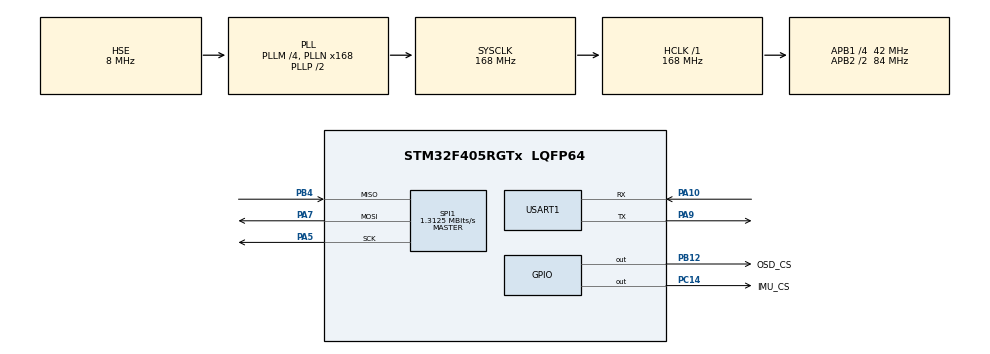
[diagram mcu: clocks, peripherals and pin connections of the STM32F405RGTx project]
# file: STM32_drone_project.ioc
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Mcu.Family=STM32F4
Mcu.Name=STM32F405RGTx
Mcu.Package=LQFP64
NVIC.PriorityGroup=NVIC_PRIORITYGROUP_4
PA10.Mode=Asynchronous
PA10.Signal=USART1_RX
PA13.Mode=Serial_Wire
PA13.Signal=SYS_JTMS-SWDIO
PA14.Mode=Serial_Wire
PA14.Signal=SYS_JTCK-SWCLK
PA5.Mode=Full_Duplex_Master
PA5.Signal=SPI1_SCK
PA7.Mode=Full_Duplex_Master
PA7.Signal=SPI1_MOSI
PA9.Mode=Asynchronous
PA9.Signal=USART1_TX
PB12.GPIO_Label=OSD_CS
PB12.GPIO_Speed=GPIO_SPEED_FREQ_LOW
PB12.PinState=GPIO_PIN_SET
PB12.Signal=GPIO_Output
PB4.Mode=Full_Duplex_Master
PB4.Signal=SPI1_MISO
PC14-OSC32_IN.GPIO_Label=IMU_CS
PC14-OSC32_IN.PinState=GPIO_PIN_SET
PC14-OSC32_IN.Signal=GPIO_Output
PH0-OSC_IN.Mode=HSE-External-Oscillator
PH0-OSC_IN.Signal=RCC_OSC_IN
PH1-OSC_OUT.Mode=HSE-External-Oscillator
PH1-OSC_OUT.Signal=RCC_OSC_OUT
ProjectManager.HeapSize=0x200
ProjectManager.StackSize=0x400
ProjectManager.TargetToolchain=STM32CubeIDE
RCC.48MHZClocksFreq_Value=84000000
RCC.AHBFreq_Value=168000000
RCC.APB1CLKDivider=RCC_HCLK_DIV4
RCC.APB1Freq_Value=42000000
RCC.APB1TimFreq_Value=84000000
RCC.APB2CLKDivider=RCC_HCLK_DIV2
RCC.APB2Freq_Value=84000000
RCC.APB2TimFreq_Value=168000000
RCC.CortexFreq_Value=168000000
RCC.HCLKFreq_Value=168000000
RCC.HSE_VALUE=8000000
RCC.HSI_VALUE=16000000
RCC.LSE_VALUE=32768
RCC.PLLM=4
RCC.PLLN=168
RCC.PLLSourceVirtual=RCC_PLLSOURCE_HSE
RCC.SYSCLKFreq_VALUE=168000000
RCC.SYSCLKSource=RCC_SYSCLKSOURCE_PLLCLK
RCC.VCOOutputFreq_Value=336000000
SPI1.BaudRatePrescaler=SPI_BAUDRATEPRESCALER_64
SPI1.CLKPhase=SPI_PHASE_2EDGE
SPI1.CLKPolarity=SPI_POLARITY_HIGH
SPI1.CalculateBaudRate=1.3125 MBits/s
SPI1.Direction=SPI_DIRECTION_2LINES
SPI1.Mode=SPI_MODE_MASTER
SPI1.VirtualType=VM_MASTER
USART1.VirtualMode=VM_ASYNC
board=custom

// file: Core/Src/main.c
/* USER CODE BEGIN Header */
/**
  ******************************************************************************
  * @file           : main.c
  * @brief          : Main program body
  ******************************************************************************
  * @attention
  *
  * Copyright (c) 2026 STMicroelectronics.
  * All rights reserved.
  *
  * This software is licensed under terms that can be found in the LICENSE file
  * in the root directory of this software component.
  * If no LICENSE file comes with this software, it is provided AS-IS.
  *
  ******************************************************************************
  */
/* USER CODE END Header */
#include "main.h"

SPI_HandleTypeDef hspi1;

UART_HandleTypeDef huart1;

/* USER CODE BEGIN PV */
volatile uint8_t g_who_am_i = 0;
volatile uint8_t g_rx0 = 0, g_rx1 = 0;
volatile int g_spi_status = -1;
/* USER CODE END PV */

void SystemClock_Config(void);
static void MX_GPIO_Init(void);
static void MX_USART1_UART_Init(void);
static void MX_SPI1_Init(void);

int main(void)
{

  /* MCU Configuration--------------------------------------------------------*/

  /* Reset of all peripherals, Initializes the Flash interface and the Systick. */
  HAL_Init();

  /* Configure the system clock */
  SystemClock_Config();

  /* Initialize all configured peripherals */
  MX_GPIO_Init();
  MX_USART1_UART_Init();
  MX_SPI1_Init();
  /* USER CODE BEGIN 2 */
	HAL_Delay(50);

	__HAL_SPI_ENABLE(&hspi1); /* ① 클록 선을 먼저 '쉬는 위치(High)'로 */
	HAL_Delay(1);

	uint8_t tx[2] = { 0x75 | 0x80, 0x00 };
	uint8_t rx[2] = { 0xAA, 0xAA }; /* ② 일부러 0이 아닌 값으로 시작 */

	HAL_GPIO_WritePin(IMU_CS_GPIO_Port, IMU_CS_Pin, GPIO_PIN_RESET);
	g_spi_status = HAL_SPI_TransmitReceive(&hspi1, tx, rx, 2, 100); /* ③ 성공 여부 저장 */
	HAL_GPIO_WritePin(IMU_CS_GPIO_Port, IMU_CS_Pin, GPIO_PIN_SET);

	g_rx0 = rx[0];
	g_rx1 = rx[1];
	g_who_am_i = rx[1];
  /* USER CODE END 2 */

  /* Infinite loop */
  while (1)
  {

  }
}

void SystemClock_Config(void)
{
  RCC_OscInitTypeDef RCC_OscInitStruct = {0};
  RCC_ClkInitTypeDef RCC_ClkInitStruct = {0};

  /** Configure the main internal regulator output voltage
  */
  __HAL_RCC_PWR_CLK_ENABLE();
  __HAL_PWR_VOLTAGESCALING_CONFIG(PWR_REGULATOR_VOLTAGE_SCALE1);

  /** Initializes the RCC Oscillators according to the specified parameters
  * in the RCC_OscInitTypeDef structure.
  */
  RCC_OscInitStruct.OscillatorType = RCC_OSCILLATORTYPE_HSE;
  RCC_OscInitStruct.HSEState = RCC_HSE_ON;
  RCC_OscInitStruct.PLL.PLLState = RCC_PLL_ON;
  RCC_OscInitStruct.PLL.PLLSource = RCC_PLLSOURCE_HSE;
  RCC_OscInitStruct.PLL.PLLM = 4;
  RCC_OscInitStruct.PLL.PLLN = 168;
  RCC_OscInitStruct.PLL.PLLP = RCC_PLLP_DIV2;
  RCC_OscInitStruct.PLL.PLLQ = 4;
  if (HAL_RCC_OscConfig(&RCC_OscInitStruct) != HAL_OK)
  {
    Error_Handler();
  }

  /** Initializes the CPU, AHB and APB buses clocks
  */
  RCC_ClkInitStruct.ClockType = RCC_CLOCKTYPE_HCLK|RCC_CLOCKTYPE_SYSCLK
                              |RCC_CLOCKTYPE_PCLK1|RCC_CLOCKTYPE_PCLK2;
  RCC_ClkInitStruct.SYSCLKSource = RCC_SYSCLKSOURCE_PLLCLK;
  RCC_ClkInitStruct.AHBCLKDivider = RCC_SYSCLK_DIV1;
  RCC_ClkInitStruct.APB1CLKDivider = RCC_HCLK_DIV4;
  RCC_ClkInitStruct.APB2CLKDivider = RCC_HCLK_DIV2;

  if (HAL_RCC_ClockConfig(&RCC_ClkInitStruct, FLASH_LATENCY_5) != HAL_OK)
  {
    Error_Handler();
  }
}

static void MX_SPI1_Init(void)
{

  /* SPI1 parameter configuration*/
  hspi1.Instance = SPI1;
  hspi1.Init.Mode = SPI_MODE_MASTER;
  hspi1.Init.Direction = SPI_DIRECTION_2LINES;
  hspi1.Init.DataSize = SPI_DATASIZE_8BIT;
  hspi1.Init.CLKPolarity = SPI_POLARITY_HIGH;
  hspi1.Init.CLKPhase = SPI_PHASE_2EDGE;
  hspi1.Init.NSS = SPI_NSS_SOFT;
  hspi1.Init.BaudRatePrescaler = SPI_BAUDRATEPRESCALER_64;
  hspi1.Init.FirstBit = SPI_FIRSTBIT_MSB;
  hspi1.Init.TIMode = SPI_TIMODE_DISABLE;
  hspi1.Init.CRCCalculation = SPI_CRCCALCULATION_DISABLE;
  hspi1.Init.CRCPolynomial = 10;
  if (HAL_SPI_Init(&hspi1) != HAL_OK)
  {
    Error_Handler();
  }

}

static void MX_USART1_UART_Init(void)
{

  huart1.Instance = USART1;
  huart1.Init.BaudRate = 115200;
  huart1.Init.WordLength = UART_WORDLENGTH_8B;
  huart1.Init.StopBits = UART_STOPBITS_1;
  huart1.Init.Parity = UART_PARITY_NONE;
  huart1.Init.Mode = UART_MODE_TX_RX;
  huart1.Init.HwFlowCtl = UART_HWCONTROL_NONE;
  huart1.Init.OverSampling = UART_OVERSAMPLING_16;
  if (HAL_UART_Init(&huart1) != HAL_OK)
  {
    Error_Handler();
  }

}

static void MX_GPIO_Init(void)
{
  GPIO_InitTypeDef GPIO_InitStruct = {0};

  /* GPIO Ports Clock Enable */
  __HAL_RCC_GPIOC_CLK_ENABLE();
  __HAL_RCC_GPIOH_CLK_ENABLE();
  __HAL_RCC_GPIOA_CLK_ENABLE();
  __HAL_RCC_GPIOB_CLK_ENABLE();

  /*Configure GPIO pin Output Level */
  HAL_GPIO_WritePin(IMU_CS_GPIO_Port, IMU_CS_Pin, GPIO_PIN_SET);

  /*Configure GPIO pin Output Level */
  HAL_GPIO_WritePin(OSD_CS_GPIO_Port, OSD_CS_Pin, GPIO_PIN_SET);

  /*Configure GPIO pin : IMU_CS_Pin */
  GPIO_InitStruct.Pin = IMU_CS_Pin;
  GPIO_InitStruct.Mode = GPIO_MODE_OUTPUT_PP;
  GPIO_InitStruct.Pull = GPIO_NOPULL;
  GPIO_InitStruct.Speed = GPIO_SPEED_FREQ_LOW;
  HAL_GPIO_Init(IMU_CS_GPIO_Port, &GPIO_InitStruct);

  /*Configure GPIO pin : OSD_CS_Pin */
  GPIO_InitStruct.Pin = OSD_CS_Pin;
  GPIO_InitStruct.Mode = GPIO_MODE_OUTPUT_PP;
  GPIO_InitStruct.Pull = GPIO_NOPULL;
  GPIO_InitStruct.Speed = GPIO_SPEED_FREQ_LOW;
  HAL_GPIO_Init(OSD_CS_GPIO_Port, &GPIO_InitStruct);

}

void Error_Handler(void)
{
  __disable_irq();
  while (1)
  {
  }
}
